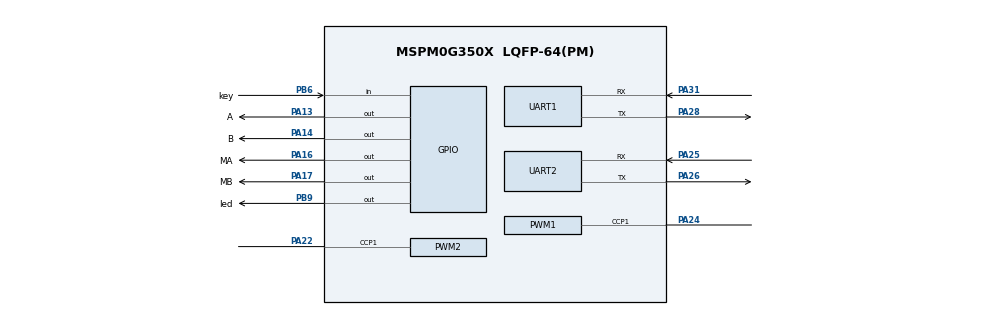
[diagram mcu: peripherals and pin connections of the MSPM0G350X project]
/**
 * @cliArgs --device "MSPM0G350X" --part "Default" --package "LQFP-64(PM)" --product "mspm0_sdk@2.11.00.07"
 * @versions {"tool":"1.26.2+4477"}
 */

/**
 * Import the modules used in this configuration.
 */
const GPIO    = scripting.addModule("/ti/driverlib/GPIO", {}, false);
const GPIO1   = GPIO.addInstance();
const GPIO2   = GPIO.addInstance();
const GPIO3   = GPIO.addInstance();
const GPIO4   = GPIO.addInstance();
const PWM     = scripting.addModule("/ti/driverlib/PWM", {}, false);
const PWM1    = PWM.addInstance();
const PWM2    = PWM.addInstance();
const SYSCTL  = scripting.addModule("/ti/driverlib/SYSCTL");
const SYSTICK = scripting.addModule("/ti/driverlib/SYSTICK");
const TIMER   = scripting.addModule("/ti/driverlib/TIMER", {}, false);
const TIMER1  = TIMER.addInstance();
const UART    = scripting.addModule("/ti/driverlib/UART", {}, false);
const UART1   = UART.addInstance();
const UART2   = UART.addInstance();

/**
 * Write custom configuration values to the imported modules.
 */
const divider7       = system.clockTree["PLL_PDIV"];
divider7.divideValue = 2;

const divider9       = system.clockTree["UDIV"];
divider9.divideValue = 2;

const gate7  = system.clockTree["MFCLKGATE"];
gate7.enable = true;

const multiplier2         = system.clockTree["PLL_QDIV"];
multiplier2.multiplyValue = 5;

const mux8       = system.clockTree["HSCLKMUX"];
mux8.inputSelect = "HSCLKMUX_SYSPLL2X";

GPIO1.$name                              = "KEY";
GPIO1.associatedPins[0].$name            = "key";
GPIO1.associatedPins[0].direction        = "INPUT";
GPIO1.associatedPins[0].internalResistor = "PULL_DOWN";
GPIO1.associatedPins[0].pin.$assign      = "PB6";

const Board = scripting.addModule("/ti/driverlib/Board", {}, false);

GPIO2.$name                         = "LED";
GPIO2.associatedPins[0].$name       = "led";
GPIO2.associatedPins[0].pin.$assign = "PB9";

GPIO3.port                          = "PORTA";
GPIO3.$name                         = "DIR";
GPIO3.associatedPins.create(2);
GPIO3.associatedPins[0].$name       = "A";
GPIO3.associatedPins[0].pin.$assign = "PA13";
GPIO3.associatedPins[1].$name       = "B";
GPIO3.associatedPins[1].pin.$assign = "PA14";

GPIO4.$name                         = "EN";
GPIO4.associatedPins.create(2);
GPIO4.associatedPins[0].$name       = "MA";
GPIO4.associatedPins[0].pin.$assign = "PA16";
GPIO4.associatedPins[1].$name       = "MB";
GPIO4.associatedPins[1].pin.$assign = "PA17";

PWM1.$name                      = "PWM_0";
PWM1.clockPrescale              = 80;
PWM1.peripheral.ccp1Pin.$assign = "PA24";
PWM1.PWM_CHANNEL_0.$name        = "ti_driverlib_pwm_PWMTimerCC0";
PWM1.PWM_CHANNEL_1.$name        = "ti_driverlib_pwm_PWMTimerCC1";
PWM1.ccp0PinConfig.$name        = "ti_driverlib_gpio_GPIOPinGeneric0";
PWM1.ccp1PinConfig.$name        = "ti_driverlib_gpio_GPIOPinGeneric1";

PWM2.$name                      = "PWM_1";
PWM2.clockPrescale              = 80;
PWM2.peripheral.ccp1Pin.$assign = "PA22";
PWM2.PWM_CHANNEL_0.$name        = "ti_driverlib_pwm_PWMTimerCC2";
PWM2.PWM_CHANNEL_1.$name        = "ti_driverlib_pwm_PWMTimerCC3";
PWM2.ccp0PinConfig.$name        = "ti_driverlib_gpio_GPIOPinGeneric4";
PWM2.ccp1PinConfig.$name        = "ti_driverlib_gpio_GPIOPinGeneric5";

SYSCTL.forceDefaultClkConfig = true;
SYSCTL.clockTreeEn           = true;

SYSTICK.periodEnable  = true;
SYSTICK.systickEnable = true;
SYSTICK.period        = 16777216;

TIMER1.$name              = "TIMER_0";
TIMER1.timerClkPrescale   = 32;
TIMER1.timerMode          = "PERIODIC";
TIMER1.timerStartTimer    = true;
TIMER1.interrupts         = ["ZERO"];
TIMER1.timerPeriod        = "5 ms";
TIMER1.peripheral.$assign = "TIMG0";

UART1.$name                    = "UART_0";
UART1.targetBaudRate           = 115200;
UART1.enabledInterrupts        = ["RX"];
UART1.peripheral.$assign       = "UART0";
UART1.peripheral.rxPin.$assign = "PA31";
UART1.peripheral.txPin.$assign = "PA28";
UART1.txPinConfig.$name        = "ti_driverlib_gpio_GPIOPinGeneric2";
UART1.rxPinConfig.$name        = "ti_driverlib_gpio_GPIOPinGeneric3";

UART2.$name                    = "UART_1";
UART2.targetBaudRate           = 115200;
UART2.enabledInterrupts        = ["RX"];
UART2.peripheral.$assign       = "UART3";
UART2.peripheral.rxPin.$assign = "PA25";
UART2.peripheral.txPin.$assign = "PA26";
UART2.txPinConfig.$name        = "ti_driverlib_gpio_GPIOPinGeneric6";
UART2.rxPinConfig.$name        = "ti_driverlib_gpio_GPIOPinGeneric7";
UART2.rxPinConfig.enableConfig     = true;
UART2.rxPinConfig.internalResistor = "PULL_UP";

/**
 * Pinmux solution for unlocked pins/peripherals. This ensures that minor changes to the automatic solver in a future
 * version of the tool will not impact the pinmux you originally saw.  These lines can be completely deleted in order to
 * re-solve from scratch.
 */
Board.peripheral.$suggestSolution          = "DEBUGSS";
Board.peripheral.swclkPin.$suggestSolution = "PA20";
Board.peripheral.swdioPin.$suggestSolution = "PA19";
PWM1.peripheral.$suggestSolution           = "TIMA1";
PWM1.peripheral.ccp0Pin.$suggestSolution   = "PA10";
PWM2.peripheral.$suggestSolution           = "TIMA0";
PWM2.peripheral.ccp0Pin.$suggestSolution   = "PA0";
